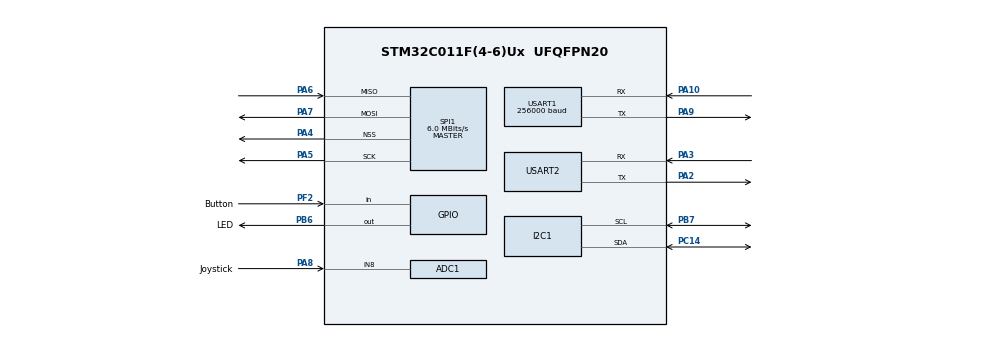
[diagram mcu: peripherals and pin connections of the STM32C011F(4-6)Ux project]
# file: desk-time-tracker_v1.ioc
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ADC1.NbrOfConversionFlag=0
ADC1.SelectedChannel=ADC_CHANNEL_8
ADC1.master=1
I2C1.Timing=0x10805D88
Mcu.Family=STM32C0
Mcu.Name=STM32C011F(4-6)Ux
Mcu.Package=UFQFPN20
NVIC.USART1_IRQn=true\:0\:0\:false\:false\:true\:true\:true\:true
PA0.Signal=S_TIM1_CH1
PA1.Signal=S_TIM1_CH2
PA10\ [PA12].Mode=Asynchronous
PA10\ [PA12].Signal=USART1_RX
PA13.Mode=Serial_Wire
PA13.Signal=DEBUG_SWDIO
PA14-BOOT0.Mode=Serial_Wire
PA14-BOOT0.Signal=DEBUG_SWCLK
PA2.Mode=Asynchronous
PA2.Signal=USART2_TX
PA3.Mode=Asynchronous
PA3.Signal=USART2_RX
PA4.Mode=NSS_Signal_Hard_Output
PA4.Signal=SPI1_NSS
PA5.Mode=Full_Duplex_Master
PA5.Signal=SPI1_SCK
PA6.Mode=Full_Duplex_Master
PA6.Signal=SPI1_MISO
PA7.Mode=Full_Duplex_Master
PA7.Signal=SPI1_MOSI
PA8.GPIO_Label=Joystick
PA8.Mode=IN8
PA8.Signal=ADC1_IN8
PA9\ [PA11].Mode=Asynchronous
PA9\ [PA11].Signal=USART1_TX
PB6.GPIO_Label=LED
PB6.GPIO_Speed=GPIO_SPEED_FREQ_VERY_HIGH
PB6.PinState=GPIO_PIN_SET
PB6.Signal=GPIO_Output
PB7.Mode=I2C
PB7.Signal=I2C1_SCL
PC14-OSCX_IN\ (PC14).Mode=I2C
PC14-OSCX_IN\ (PC14).Signal=I2C1_SDA
PF2-NRST.GPIO_Label=Button
PF2-NRST.Signal=GPIO_Input
ProjectManager.HeapSize=0x200
ProjectManager.StackSize=0x400
ProjectManager.TargetToolchain=STM32CubeIDE
RCC.ADCFreq_Value=48000000
RCC.AHBFreq_Value=48000000
RCC.CortexFreq_Value=48000000
RCC.EXTERNAL_CLOCK_VALUE=12288000
RCC.HCLKFreq_Value=48000000
RCC.HSE_VALUE=8000000
RCC.HSISYSCLKDivider=RCC_HSI_DIV1
RCC.HSI_VALUE=48000000
RCC.LSE_VALUE=32768
RCC.SYSCLKFreq_VALUE=48000000
SH.S_TIM1_CH1.0=TIM1_CH1
SH.S_TIM1_CH2.0=TIM1_CH2
SPI1.BaudRatePrescaler=SPI_BAUDRATEPRESCALER_8
SPI1.CalculateBaudRate=6.0 MBits/s
SPI1.Direction=SPI_DIRECTION_2LINES
SPI1.Mode=SPI_MODE_MASTER
SPI1.VirtualNSS=VM_NSSHARD
SPI1.VirtualType=VM_MASTER
USART1.BaudRate=256000
USART1.VirtualMode-Asynchronous=VM_ASYNC
USART2.VirtualMode-Asynchronous=VM_ASYNC
VP_SYS_VS_PINREMAP.Mode=PINREMAP
VP_SYS_VS_PINREMAP_10_12.Mode=PINREMAP_10_12
board=STM32C0116-DK

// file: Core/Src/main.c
/* USER CODE BEGIN Header */
/**
  ******************************************************************************
  * @file           : main.c
  * @brief          : Main program body
  ******************************************************************************
  * @attention
  *
  * Copyright (c) 2025 STMicroelectronics.
  * All rights reserved.
  *
  * This software is licensed under terms that can be found in the LICENSE file
  * in the root directory of this software component.
  * If no LICENSE file comes with this software, it is provided AS-IS.
  *
  ******************************************************************************
  */

/**
 *
 * Desk Timer Tracker
 *
 * The Desk Timer Tracker is a basic system which will use a mmWave sensor to detect
 * human presence, monitor how long the person has been present, and display the timer
 * on a OLED screen. The system will also include a small, FRAM chip which will store and
 * keep track of the average time spent, which will also be displayed on the OLED screen.
 *
 * Requirements:
 * 	- Low Power System
 * 	- mmWave activates, signaling a timer to begin incrementing.
 * 	- OLED monitor displays time on screen, will be off if no presence is detected
 * 	- once presence is not detected, begin a 5 minute timer to end the session, can be interrupted
 * 	- once session is ended, store the final time in FRAM
 * 	- once woken up, update the average in a smaller portion of the screen.
 *
 * 	Specifics
 * 	 - mmWave Sensor
 * 	 	a. Configurable through a UART communication protocol, see datasheet for specifics (2.2)
 * 	 	b. Recieves motion detection through serial port, with a lot of information (2.3)
 * 	 	PINS: [PA9 (Tx), PA10 (Rx)]
 *
 * 	 - OLED Screen
 * 	 	a. 128x64 pixel active area
 * 	 	b. datasheet is nonexistant...
 * 	 	c. Need to figure out how to write to screen
 * 	 	PINS: [PB7 (SCL), PC14 (SDA)]
 *
 * 	 - FRAM
 * 	 	.a Detailed Datasheet
 * 	 	b. Also uses i2c so will need to figure that out...
 * 	 	PINS: [PB7 (SCL), PC14 (SDA)]
 *
 */

/* USER CODE END Header */
#include "main.h"

ADC_HandleTypeDef hadc1;

I2C_HandleTypeDef hi2c1;

SPI_HandleTypeDef hspi1;

UART_HandleTypeDef huart1;
UART_HandleTypeDef huart2;

void SystemClock_Config(void);
static void MX_GPIO_Init(void);
static void MX_ADC1_Init(void);
static void MX_SPI1_Init(void);
static void MX_USART1_UART_Init(void);
static void MX_USART2_UART_Init(void);
static void MX_I2C1_Init(void);

int main(void)
{

  /* MCU Configuration--------------------------------------------------------*/

  /* Reset of all peripherals, Initializes the Flash interface and the Systick. */
  HAL_Init();

  /* Configure the system clock */
  SystemClock_Config();

  /* USER CODE BEGIN SysInit */

  /* USER COD			E END SysInit */

  /* Initialize all configured peripherals */
  MX_GPIO_Init();
  MX_ADC1_Init();
  MX_SPI1_Init();
  MX_USART1_UART_Init();
  MX_USART2_UART_Init();
  MX_I2C1_Init();

  /* Infinite loop */
  /* USER CODE BEGIN WHILE */
  while (1)
  {
	//User code go here
    /* USER CODE END WHILE */

  }
}

void SystemClock_Config(void)
{
  RCC_OscInitTypeDef RCC_OscInitStruct = {0};
  RCC_ClkInitTypeDef RCC_ClkInitStruct = {0};

  __HAL_FLASH_SET_LATENCY(FLASH_LATENCY_1);

  /** Initializes the RCC Oscillators according to the specified parameters
  * in the RCC_OscInitTypeDef structure.
  */
  RCC_OscInitStruct.OscillatorType = RCC_OSCILLATORTYPE_HSI;
  RCC_OscInitStruct.HSIState = RCC_HSI_ON;
  RCC_OscInitStruct.HSIDiv = RCC_HSI_DIV1;
  RCC_OscInitStruct.HSICalibrationValue = RCC_HSICALIBRATION_DEFAULT;
  if (HAL_RCC_OscConfig(&RCC_OscInitStruct) != HAL_OK)
  {
    Error_Handler();
  }

  /** Initializes the CPU, AHB and APB buses clocks
  */
  RCC_ClkInitStruct.ClockType = RCC_CLOCKTYPE_HCLK|RCC_CLOCKTYPE_SYSCLK
                              |RCC_CLOCKTYPE_PCLK1;
  RCC_ClkInitStruct.SYSCLKSource = RCC_SYSCLKSOURCE_HSI;
  RCC_ClkInitStruct.SYSCLKDivider = RCC_SYSCLK_DIV1;
  RCC_ClkInitStruct.AHBCLKDivider = RCC_HCLK_DIV1;
  RCC_ClkInitStruct.APB1CLKDivider = RCC_APB1_DIV1;

  if (HAL_RCC_ClockConfig(&RCC_ClkInitStruct, FLASH_LATENCY_1) != HAL_OK)
  {
    Error_Handler();
  }
}

static void MX_ADC1_Init(void)
{

  ADC_ChannelConfTypeDef sConfig = {0};

  /** Configure the global features of the ADC (Clock, Resolution, Data Alignment and number of conversion)
  */
  hadc1.Instance = ADC1;
  hadc1.Init.ClockPrescaler = ADC_CLOCK_SYNC_PCLK_DIV2;
  hadc1.Init.Resolution = ADC_RESOLUTION_12B;
  hadc1.Init.DataAlign = ADC_DATAALIGN_RIGHT;
  hadc1.Init.ScanConvMode = ADC_SCAN_SEQ_FIXED;
  hadc1.Init.EOCSelection = ADC_EOC_SINGLE_CONV;
  hadc1.Init.LowPowerAutoWait = DISABLE;
  hadc1.Init.LowPowerAutoPowerOff = DISABLE;
  hadc1.Init.ContinuousConvMode = DISABLE;
  hadc1.Init.NbrOfConversion = 1;
  hadc1.Init.DiscontinuousConvMode = DISABLE;
  hadc1.Init.ExternalTrigConv = ADC_SOFTWARE_START;
  hadc1.Init.ExternalTrigConvEdge = ADC_EXTERNALTRIGCONVEDGE_NONE;
  hadc1.Init.DMAContinuousRequests = DISABLE;
  hadc1.Init.Overrun = ADC_OVR_DATA_PRESERVED;
  hadc1.Init.SamplingTimeCommon1 = ADC_SAMPLETIME_1CYCLE_5;
  hadc1.Init.OversamplingMode = DISABLE;
  hadc1.Init.TriggerFrequencyMode = ADC_TRIGGER_FREQ_HIGH;
  if (HAL_ADC_Init(&hadc1) != HAL_OK)
  {
    Error_Handler();
  }

  /** Configure Regular Channel
  */
  sConfig.Channel = ADC_CHANNEL_8;
  sConfig.Rank = ADC_RANK_CHANNEL_NUMBER;
  if (HAL_ADC_ConfigChannel(&hadc1, &sConfig) != HAL_OK)
  {
    Error_Handler();
  }

}

static void MX_I2C1_Init(void)
{

  hi2c1.Instance = I2C1;
  hi2c1.Init.Timing = 0x10805D88;
  hi2c1.Init.OwnAddress1 = 0;
  hi2c1.Init.AddressingMode = I2C_ADDRESSINGMODE_7BIT;
  hi2c1.Init.DualAddressMode = I2C_DUALADDRESS_DISABLE;
  hi2c1.Init.OwnAddress2 = 0;
  hi2c1.Init.OwnAddress2Masks = I2C_OA2_NOMASK;
  hi2c1.Init.GeneralCallMode = I2C_GENERALCALL_DISABLE;
  hi2c1.Init.NoStretchMode = I2C_NOSTRETCH_DISABLE;
  if (HAL_I2C_Init(&hi2c1) != HAL_OK)
  {
    Error_Handler();
  }

  /** Configure Analogue filter
  */
  if (HAL_I2CEx_ConfigAnalogFilter(&hi2c1, I2C_ANALOGFILTER_ENABLE) != HAL_OK)
  {
    Error_Handler();
  }

  /** Configure Digital filter
  */
  if (HAL_I2CEx_ConfigDigitalFilter(&hi2c1, 0) != HAL_OK)
  {
    Error_Handler();
  }

}

static void MX_SPI1_Init(void)
{

  /* SPI1 parameter configuration*/
  hspi1.Instance = SPI1;
  hspi1.Init.Mode = SPI_MODE_MASTER;
  hspi1.Init.Direction = SPI_DIRECTION_2LINES;
  hspi1.Init.DataSize = SPI_DATASIZE_8BIT;
  hspi1.Init.CLKPolarity = SPI_POLARITY_LOW;
  hspi1.Init.CLKPhase = SPI_PHASE_1EDGE;
  hspi1.Init.NSS = SPI_NSS_HARD_OUTPUT;
  hspi1.Init.BaudRatePrescaler = SPI_BAUDRATEPRESCALER_8;
  hspi1.Init.FirstBit = SPI_FIRSTBIT_MSB;
  hspi1.Init.TIMode = SPI_TIMODE_DISABLE;
  hspi1.Init.CRCCalculation = SPI_CRCCALCULATION_DISABLE;
  hspi1.Init.CRCPolynomial = 7;
  hspi1.Init.CRCLength = SPI_CRC_LENGTH_DATASIZE;
  hspi1.Init.NSSPMode = SPI_NSS_PULSE_ENABLE;
  if (HAL_SPI_Init(&hspi1) != HAL_OK)
  {
    Error_Handler();
  }

}

static void MX_USART1_UART_Init(void)
{

  huart1.Instance = USART1;
  huart1.Init.BaudRate = 256000;
  huart1.Init.WordLength = UART_WORDLENGTH_8B;
  huart1.Init.StopBits = UART_STOPBITS_1;
  huart1.Init.Parity = UART_PARITY_NONE;
  huart1.Init.Mode = UART_MODE_TX_RX;
  huart1.Init.HwFlowCtl = UART_HWCONTROL_NONE;
  huart1.Init.OverSampling = UART_OVERSAMPLING_16;
  huart1.Init.OneBitSampling = UART_ONE_BIT_SAMPLE_DISABLE;
  huart1.Init.ClockPrescaler = UART_PRESCALER_DIV1;
  huart1.AdvancedInit.AdvFeatureInit = UART_ADVFEATURE_NO_INIT;
  if (HAL_UART_Init(&huart1) != HAL_OK)
  {
    Error_Handler();
  }
  if (HAL_UARTEx_SetTxFifoThreshold(&huart1, UART_TXFIFO_THRESHOLD_1_8) != HAL_OK)
  {
    Error_Handler();
  }
  if (HAL_UARTEx_SetRxFifoThreshold(&huart1, UART_RXFIFO_THRESHOLD_1_8) != HAL_OK)
  {
    Error_Handler();
  }
  if (HAL_UARTEx_DisableFifoMode(&huart1) != HAL_OK)
  {
    Error_Handler();
  }

}

static void MX_USART2_UART_Init(void)
{

  huart2.Instance = USART2;
  huart2.Init.BaudRate = 115200;
  huart2.Init.WordLength = UART_WORDLENGTH_8B;
  huart2.Init.StopBits = UART_STOPBITS_1;
  huart2.Init.Parity = UART_PARITY_NONE;
  huart2.Init.Mode = UART_MODE_TX_RX;
  huart2.Init.HwFlowCtl = UART_HWCONTROL_NONE;
  huart2.Init.OverSampling = UART_OVERSAMPLING_16;
  huart2.Init.OneBitSampling = UART_ONE_BIT_SAMPLE_DISABLE;
  huart2.Init.ClockPrescaler = UART_PRESCALER_DIV1;
  huart2.AdvancedInit.AdvFeatureInit = UART_ADVFEATURE_NO_INIT;
  if (HAL_UART_Init(&huart2) != HAL_OK)
  {
    Error_Handler();
  }

}

static void MX_GPIO_Init(void)
{
  GPIO_InitTypeDef GPIO_InitStruct = {0};

  /* GPIO Ports Clock Enable */
  __HAL_RCC_GPIOF_CLK_ENABLE();
  __HAL_RCC_GPIOA_CLK_ENABLE();
  __HAL_RCC_GPIOB_CLK_ENABLE();
  __HAL_RCC_GPIOC_CLK_ENABLE();

  /*Configure GPIO pin Output Level */
  HAL_GPIO_WritePin(LED_GPIO_Port, LED_Pin, GPIO_PIN_SET);

  /*Configure GPIO pin : Button_Pin */
  GPIO_InitStruct.Pin = Button_Pin;
  GPIO_InitStruct.Mode = GPIO_MODE_INPUT;
  GPIO_InitStruct.Pull = GPIO_NOPULL;
  HAL_GPIO_Init(Button_GPIO_Port, &GPIO_InitStruct);

  /*Configure GPIO pins : PA0 PA1 */
  GPIO_InitStruct.Pin = GPIO_PIN_0|GPIO_PIN_1;
  GPIO_InitStruct.Mode = GPIO_MODE_AF_PP;
  GPIO_InitStruct.Pull = GPIO_NOPULL;
  GPIO_InitStruct.Speed = GPIO_SPEED_FREQ_LOW;
  GPIO_InitStruct.Alternate = GPIO_AF5_TIM1;
  HAL_GPIO_Init(GPIOA, &GPIO_InitStruct);

  /*Configure GPIO pin : LED_Pin */
  GPIO_InitStruct.Pin = LED_Pin;
  GPIO_InitStruct.Mode = GPIO_MODE_OUTPUT_PP;
  GPIO_InitStruct.Pull = GPIO_NOPULL;
  GPIO_InitStruct.Speed = GPIO_SPEED_FREQ_VERY_HIGH;
  HAL_GPIO_Init(LED_GPIO_Port, &GPIO_InitStruct);

}

void Error_Handler(void)
{
  __disable_irq();
  while (1)
  {
  }
}
